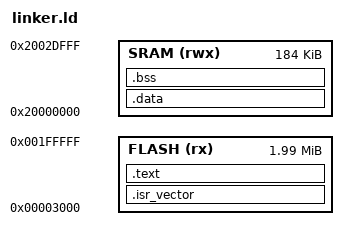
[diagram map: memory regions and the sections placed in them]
ENTRY(Reset_Handler)

MEMORY
{
    FLASH (rx)  : ORIGIN = 0x00003000, LENGTH = 0x001fd000
    SRAM  (rwx) : ORIGIN = 0x20000000, LENGTH = 0x0002e000
}

_stack_top = ORIGIN(SRAM) + LENGTH(SRAM);

SECTIONS
{
    .isr_vector ORIGIN(FLASH) :
    {
        KEEP(*(.isr_vector))
    } > FLASH

    .text :
    {
        . = ALIGN(4);
        KEEP(*(.text.Reset_Handler))
        *(.text*)
        *(.rodata*)
        . = ALIGN(4);
        _etext = .;
    } > FLASH

    .data : AT(_etext)
    {
        . = ALIGN(4);
        _sdata = .;
        *(.data*)
        . = ALIGN(4);
        _edata = .;
    } > SRAM
    _sidata = LOADADDR(.data);

    .bss (NOLOAD) :
    {
        . = ALIGN(4);
        _sbss = .;
        *(.bss*)
        *(COMMON)
        . = ALIGN(4);
        _ebss = .;
    } > SRAM

    /DISCARD/ : { *(.comment*) *(.note*) }
}

ASSERT(SIZEOF(.isr_vector) == 0x1f0, "vector table must match observed 0x1f0-byte layout")
ASSERT(_ebss <= _stack_top, "SRAM overflow")
